# MKW38A4 register map
Vendor: NXP Semiconductors; Series: Kinetis_W; File version: 1.6
CPU: CM0PLUS r0p0, little endian, no MPU, no FPU, VTOR, 2 interrupt priority bits
Registers are 32-bit, read-write, no defined reset value unless marked. A register's access mark holds for its fields unless they carry their own. Offsets are from the block's base; [hi:lo] are bit positions; {n}, {i} and the like mark numbered series; 'fields as' and 'values as' point back to an identical list.

## XCVR_MISC
Base 0x40087280
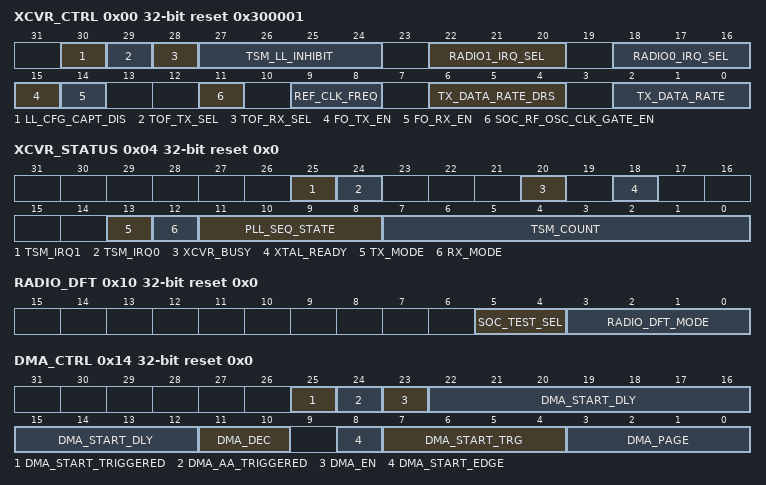
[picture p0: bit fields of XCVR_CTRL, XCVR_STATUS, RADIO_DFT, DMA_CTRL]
0x00 XCVR_CTRL reset 0x300001 — TRANSCEIVER CONTROL
  [30] LL_CFG_CAPT_DIS — Link Layer Configuration Capture Disable
    0=Enabled. Link Layer configuration inputs are captured.; 1=Disabled: Link Layer configurations are not captured
  [29] TOF_TX_SEL — Time-of-Flight TX Select
    0=TSM: tx_dig_en; 1=TXDIG: pa_wu_complete
  [28] TOF_RX_SEL — Time-of-Flight RX Select
    0=PHY: aa_fnd_to_ll; 1=Localization Control: pattern_found
  [27:24] TSM_LL_INHIBIT — TSM Per-Link-Layer Inhibit
  [22:20] RADIO1_IRQ_SEL
    0=Assign Radio #1 Interrupt to Bluetooth LE; 1=Radio #1 Interrupt unassigned; 2=Radio #1 Interrupt unassigned; 3=Assign Radio #1 Interrupt to GENERIC_FSK; {v}=Radio #1 Interrupt unassigned (v=4..7)
  [18:16] RADIO0_IRQ_SEL
    0=Assign Radio #0 Interrupt to Bluetooth LE; 1=Radio #0 Interrupt unassigned; 2=Radio #0 Interrupt unassigned; 3=Assign Radio #0 Interrupt to GENERIC_FSK; {v}=Radio #0 Interrupt unassigned (v=4..7)
  [15] FO_TX_EN — Fast Overwrite TX Enable
  [14] FO_RX_EN — Fast Overwrite RX Enable
  [11] SOC_RF_OSC_CLK_GATE_EN
  [9:8] REF_CLK_FREQ — Radio Reference Clock Frequency
    0=32 MHz; 1=26 MHz
  [6:4] TX_DATA_RATE_DRS — Radio data rate setting, Data Rate Switch
    0=2Mbps; 1=1Mbps; 2=500Kbps; 3=250Kbps
  [2:0] TX_DATA_RATE — Radio data rate setting
    0=2Mbps; 1=1Mbps; 2=500Kbps; 3=250Kbps
0x04 XCVR_STATUS reset 0x0 (reset mask 0xFFFBC000) — TRANSCEIVER STATUS
  [25] TSM_IRQ1 — TSM Interrupt #1
    0=TSM Interrupt #1 is not asserted; 1=TSM Interrupt #1 is asserted. Write '1' to this bit to clear it.
  [24] TSM_IRQ0 — TSM Interrupt #0
    0=TSM Interrupt #0 is not asserted; 1=TSM Interrupt #0 is asserted. Write '1' to this bit to clear it.
  [20] XCVR_BUSY ro — Transceiver Busy Status Bit
    0=RF Channel in available (TSM is idle); 1=RF Channel in use (TSM is busy)
  [18] XTAL_READY ro — RF Osciallator Xtal Ready
    0=Indicates that the RF Oscillator is disabled or has not completed its warmup; 1=Indicates that the RF Oscillator has completed its warmup count and is ready for use
  [13] TX_MODE ro — Transmit Mode
  [12] RX_MODE ro — Receive Mode
  [11:8] PLL_SEQ_STATE ro — PLL Sequence State
    0=PLL OFF; 2=CTUNE; 3=CTUNE_SETTLE; 6=HPMCAL1; 8=HPMCAL1_SETTLE; 10=HPMCAL2; 12=HPMCAL2_SETTLE; 15=PLLREADY
  [7:0] TSM_COUNT ro
0x0C OVERWRITE_VER reset 0x0 — OVERWRITE VERSION
  [7:0] OVERWRITE_VER — Overwrite Version Number.
0x10 RADIO_DFT reset 0x0
  [5:4] SOC_TEST_SEL — Radio Clock Selector for SoC RF Clock Tests
    0=No Clock Selected; 1=PLL Sigma Delta Clock, divided by 2; 2=Auxiliary PLL Clock, divided by 2; 3=RF Ref Osc clock, divided by 2
  [3:0] RADIO_DFT_MODE — Radio DFT modes
    0=Normal Radio Operation, DFT not engaged; 1=Carrier Only; 2=Pattern Register GFSK; 3=LFSR; 4=RAM Modulation; 10=PLL Coarse Tune BIST; 11=PLL Frequency Synthesizer BIST; 12=High Port DAC BIST; 13=VCO Frequency Meter
0x14 DMA_CTRL reset 0x0 — DMA CONTROL
  [25] DMA_START_TRIGGERED ro — DMA Start Trigger Occurred
  [24] DMA_AA_TRIGGERED ro — DMA Access Address triggered
  [23] DMA_EN — DMA Enable
  [22:12] DMA_START_DLY — DMA Start Trigger Delay
  [11:10] DMA_DEC — DMA Decimation Rate
    0=Data is captured on every data valid; 1=Data is captured on every 2nd data valid; 2=Data is captured on everey 4th data valid; 3=Data is captured on every 8th data valid
  [8] DMA_START_EDGE — DMA Start Trigger Edge Selector
    0=Trigger fires on a rising edge of the selected trigger source; 1=Trigger fires on a falling edge of the selected trigger source
  [7:4] DMA_START_TRG — DMA Start Trigger Selector
    0=no trigger; 1=PHY: pd found; 2=PHY: aa found; 5=RXDIG: agc_dcoc_gain_chg; 6=TSM: rx_dig_en; 7=TSM: tsm_spare2_en; 8=RBME: crc_pass; 9=RBME: crc_vld; 10=Localization control: dma_capt_trig; 11=GenericLL: cte_present
  [3:0] DMA_PAGE — Transceiver DMA Page Selector
    0=DMA idle; 1=RXDIG-IQ; 2=RXDIG-IQ-ALT; 3=ADC-IQ; 4=DCEST-IQ; 5=PHASE; 6=RSSI-PHASE; 7=MAG-PHASE; 8=PHY; 9=DETERMINISTIC
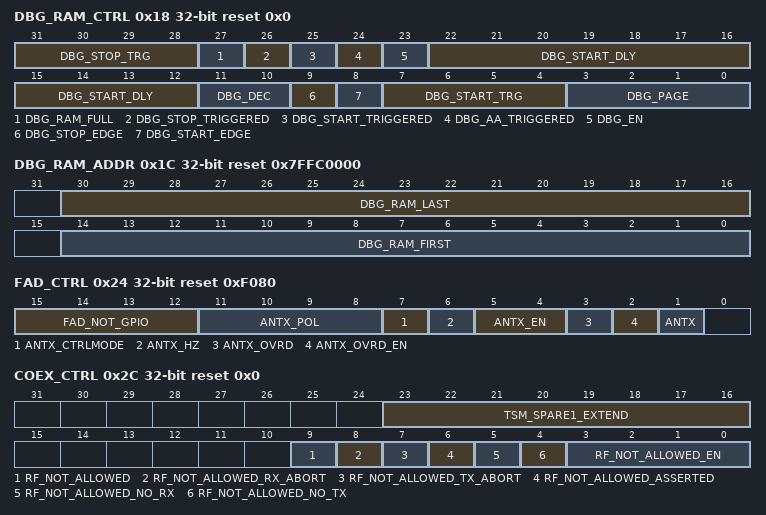
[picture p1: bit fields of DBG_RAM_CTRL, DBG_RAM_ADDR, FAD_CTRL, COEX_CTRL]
0x18 DBG_RAM_CTRL reset 0x0 — DBG RAM CONTROL
  [31:28] DBG_STOP_TRG — Packet RAM Debug Stop Trigger Selector
    0=no trigger; 1=PHY: pd found; 2=PHY: aa found; 5=RXDIG: agc_dcoc_gain_chg; 6=TSM: rx_dig_en; 7=TSM: tsm_spare3_en; 8=RBME: crc_fail; 9=RBME: crc_vld; 10=RBME: error; 11=Generic header fail; 12=PLL unlock; 13=Bluetooth LE crc_err_count_incr
  [27] DBG_RAM_FULL ro
    0=Packet RAM is not full; 1=Packet RAM is full
  [26] DBG_STOP_TRIGGERED ro — Packet RAM Debug Stop Triggered
  [25] DBG_START_TRIGGERED ro — Packet RAM Debug Start Triggered
  [24] DBG_AA_TRIGGERED ro — Packet Ram Debug Access Address triggered
  [23] DBG_EN — Packet RAM Debug Mode Enable
  [22:12] DBG_START_DLY — DBG Start Trigger Delay
  [11:10] DBG_DEC — DBG Decimation Rate
    values as DMA_CTRL.DMA_DEC
  [9] DBG_STOP_EDGE — Packet RAM Debug Stop Trigger Edge Selector
    values as DMA_CTRL.DMA_START_EDGE
  [8] DBG_START_EDGE — Packet RAM Debug Start Trigger Edge Selector
    values as DMA_CTRL.DMA_START_EDGE
  [7:4] DBG_START_TRG — Packet RAM Debug Start Trigger Selector
    values as DMA_CTRL.DMA_START_TRG
  [3:0] DBG_PAGE — Packet RAM Debug DMA Page Selector
    0=DMA idle; 1=RXDIG-IQ; 2=RXDIG-IQ-ALT; 3=ADC-IQ; 4=DCEST-IQ; 5=PHASE; 6=RSSI-PHASE; 7=MAG-PHASE; 8=PHY
0x1C DBG_RAM_ADDR reset 0x7FFC0000 — DBG RAM ADDRESS
  [30:16] DBG_RAM_LAST — DBG RAM Last Address
  [14:0] DBG_RAM_FIRST — DBG RAM First Address
0x20 DBG_RAM_STOP_ADDR ro reset 0x0 — DBG RAM STOP ADDRESS
  [14:0] DBG_RAM_STOP — DBG RAM Stop Address
0x24 FAD_CTRL reset 0xF080 — FAD CONTROL
  [15:12] FAD_NOT_GPIO — FAD versus GPIO Mode Selector
  [11:8] ANTX_POL — FAD Antenna Controls Polarity
  [7] ANTX_CTRLMODE — Antenna Diversity Control Mode
  [6] ANTX_HZ — FAD PAD Tristate Control
    0=ANT_A, ANT_B, RX_SWITCH and TX_SWITCH are actively driven outputs; 1=Antenna controls high impedance- Set ANT_A, ANT_B, RX_SWITCH and TX_SWITCH in high impedance
  [5:4] ANTX_EN — FAD Antenna Controls Enable
    0=all disabled (held low); 1=only RX/TX_SWITCH enabled; 2=only ANT_A/B enabled; 3=all enabled
  [3] ANTX_OVRD — Antenna State Override Value
  [2] ANTX_OVRD_EN — Antenna State Override Enable
  [1] ANTX ro — Antenna Selection State
0x2C COEX_CTRL reset 0x0 — COEXISTENCE CONTROL
  [23:16] TSM_SPARE1_EXTEND — TSM_SPARE1_EX Extension Duration
  [9] RF_NOT_ALLOWED ro
  [8] RF_NOT_ALLOWED_RX_ABORT
    0=A RX abort due to assertion on RF_NOT_ALLOWED has not occurred; 1=A RX abort due to assertion on RF_NOT_ALLOWED has occurred since the last time this bit was cleared
  [7] RF_NOT_ALLOWED_TX_ABORT
    0=A TX abort due to assertion on RF_NOT_ALLOWED has not occurred; 1=A TX abort due to assertion on RF_NOT_ALLOWED has occurred since the last time this bit was cleared
  [6] RF_NOT_ALLOWED_ASSERTED
    0=Assertion on RF_NOT_ALLOWED has not occurred; 1=Assertion on RF_NOT_ALLOWED has occurred since the last time this bit was cleared
  [5] RF_NOT_ALLOWED_NO_RX
    0=Assertion on RF_NOT_ALLOWED has no effect on RX; 1=Assertion on RF_NOT_ALLOWED can abort RX
  [4] RF_NOT_ALLOWED_NO_TX
    0=Assertion on RF_NOT_ALLOWED has no effect on TX; 1=Assertion on RF_NOT_ALLOWED can abort TX
  [3:0] RF_NOT_ALLOWED_EN — RF_NOT_ALLOWED PER-LINK-LAYER ENABLE
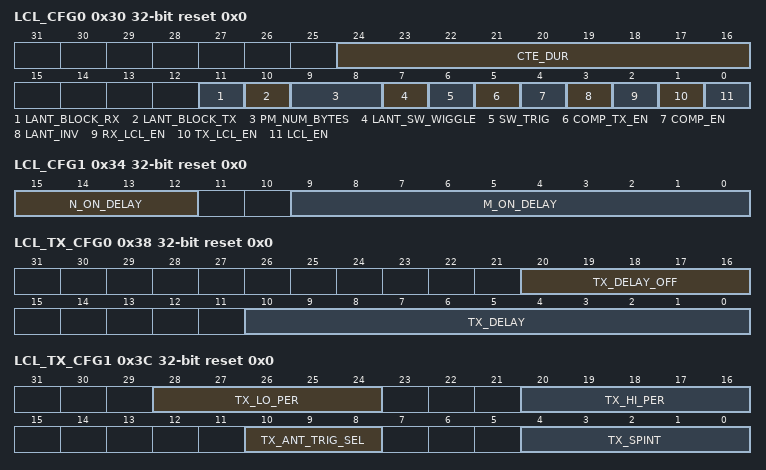
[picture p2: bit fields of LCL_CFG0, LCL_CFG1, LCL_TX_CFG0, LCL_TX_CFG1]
0x30 LCL_CFG0 reset 0x0 — LOCALIZATION CONTROL CONFIG0
  [24:16] CTE_DUR — Total Switching Duration
  [11] LANT_BLOCK_RX — Block LANT_SW for RX
  [10] LANT_BLOCK_TX — Block LANT_SW for TX
  [9:8] PM_NUM_BYTES — Number of Bytes to Match
    0=4 bytes; 1=5 bytes; 2=6 bytes; 3=8 bytes
  [7] LANT_SW_WIGGLE
  [6] SW_TRIG — Software Trigger. Can be used with either RX or TX
  [5] COMP_TX_EN — Pattern Matching Enable in TX
  [4] COMP_EN — Pattern Matching Enable
  [3] LANT_INV — Invert Antenna Switch Output
  [2] RX_LCL_EN — Enable Switching in RX
  [1] TX_LCL_EN — Enable Switching in TX
  [0] LCL_EN — Localization Control Module Enable
0x34 LCL_CFG1 reset 0x0 — LOCALIZATION CONTROL CONFIG1
  [15:12] N_ON_DELAY, [9:0] M_ON_DELAY
0x38 LCL_TX_CFG0 reset 0x0 — LOCALIZATION CONTROL TX CONFIG0
  [20:16] TX_DELAY_OFF — Fine sample delay after TX_DELAY.
  [10:0] TX_DELAY — Interval delay before TX switching begins.
0x3C LCL_TX_CFG1 reset 0x0 — LOCALIZATION CONTROL TX CONFIG1
  [28:24] TX_LO_PER — Number of intervals for antenna LOW
  [20:16] TX_HI_PER — Number of intervals for antenna HIGH
  [10:8] TX_ANT_TRIG_SEL — Selects Trigger for TX
    0=Software Trigger; 1=Localization control: pattern found; 2=CRC Complete; 3=PA Warmup Complete; 4=RBME tx_done_pre
  [4:0] TX_SPINT — Number of TX Samples that define the length of an Interval , where 0=1sample, 1=2sample, etc.
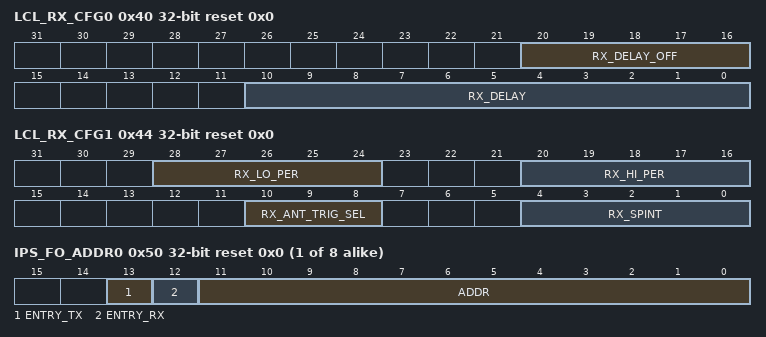
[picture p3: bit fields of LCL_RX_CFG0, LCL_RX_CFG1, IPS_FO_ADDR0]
0x40 LCL_RX_CFG0 reset 0x0 — LOCALIZATION CONTROL RX CONFIG0
  [20:16] RX_DELAY_OFF — Fine sample delay after RX_DELAY.
  [10:0] RX_DELAY — Interval delay before RX switching begins.
0x44 LCL_RX_CFG1 reset 0x0 — LOCALIZATION CONTROL RX CONFIG1
  [28:24] RX_LO_PER — Number of intervals for antenna LOW
  [20:16] RX_HI_PER — Number of intervals for antenna HIGH
  [10:8] RX_ANT_TRIG_SEL — Selects Trigger for RX
    0=Software Trigger; 1=Localization control: pattern found; 2=CRC Complete; 3=CRC Pass; 4=GenericLL: cte_present; 5=PHY: aa_fnd_to_ll
  [4:0] RX_SPINT — Number of RX Samples that define the length of an Interval , where 0=1sample, 1=2sample, etc.
0x48 LCL_PM_MSB reset 0x0 — LOCALIZATION CONTROL PM MSB
  [31:0] COMP_PATTERN_MSB — Upper bytes of pattern to be matched, bits 63:32
0x4C LCL_PM_LSB reset 0x0 — LOCALIZATION CONTROL PM LSB
  [31:0] COMP_PATTERN_LSB — Lower bytes of pattern to be matched, bits 31:0
{0x50+4i} IPS_FO_ADDR{i} reset 0x0 (i=0..7) — IPS FAST OVERWRITE ADDRESS
  [13] ENTRY_TX — Enable Entry for TX
  [12] ENTRY_RX — Enable Entry for RX
  [11:0] ADDR — IPS Address
{0x70+4i} IPS_FO_DRS0_DATA{i} reset 0x0 (i=0..7) — IPS FAST OVERWRITE DRS0 DATA
  [31:0] DRS0_DATA — Fast Overwrite DRS0 data
{0x90+4i} IPS_FO_DRS1_DATA{i} reset 0x0 (i=0..7) — IPS FAST OVERWRITE DRS1 DATA
  [31:0] DRS1_DATA — Fast Overwrite DRS1 data
